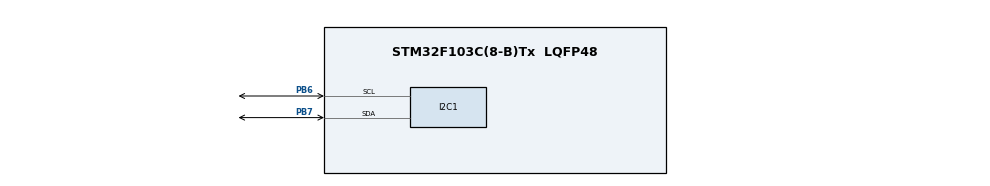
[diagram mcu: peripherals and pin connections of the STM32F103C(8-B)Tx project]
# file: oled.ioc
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Mcu.Family=STM32F1
Mcu.Name=STM32F103C(8-B)Tx
Mcu.Package=LQFP48
NVIC.PriorityGroup=NVIC_PRIORITYGROUP_4
PA13.Mode=Serial_Wire
PA13.Signal=SYS_JTMS-SWDIO
PA14.Mode=Serial_Wire
PA14.Signal=SYS_JTCK-SWCLK
PB6.Mode=I2C
PB6.Signal=I2C1_SCL
PB7.Mode=I2C
PB7.Signal=I2C1_SDA
ProjectManager.HeapSize=0x200
ProjectManager.StackSize=0x400
ProjectManager.TargetToolchain=STM32CubeIDE
RCC.APB1Freq_Value=8000000
RCC.APB2Freq_Value=8000000
board=custom

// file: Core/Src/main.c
/* USER CODE BEGIN Header */
/**
  ******************************************************************************
  * @file           : main.c
  * @brief          : Main program body
  ******************************************************************************
  * @attention
  *
  * <h2><center>&copy; Copyright (c) 2022 STMicroelectronics.
  * All rights reserved.</center></h2>
  *
  * This software component is licensed by ST under BSD 3-Clause license,
  * the "License"; You may not use this file except in compliance with the
  * License. You may obtain a copy of the License at:
  *                        opensource.org/licenses/BSD-3-Clause
  *
  ******************************************************************************
  */
/* USER CODE END Header */
#include "main.h"

/* USER CODE BEGIN Includes */
#include "oled_driver.h"

/* USER CODE END Includes */

I2C_HandleTypeDef hi2c1;

/* USER CODE BEGIN PV */
const uint8_t img[1024] = {
0X00,0X00,0X00,0X00,0X00,0X00,0X00,0X00,0X00,0X00,0X00,0X00,0X00,0X00,0X00,0X00,
0X00,0X00,0X00,0X00,0X00,0X00,0X00,0X00,0X00,0X00,0X00,0X00,0X00,0X00,0X00,0X00,
0X00,0X00,0X00,0X00,0X00,0X00,0X00,0X00,0X00,0X00,0X00,0X00,0X00,0X00,0X00,0X00,
0X00,0X00,0X00,0X00,0X00,0X00,0X00,0X00,0X00,0X00,0X00,0X00,0X00,0X00,0X00,0X00,
0X00,0X00,0X00,0X00,0X00,0X00,0X00,0X00,0X00,0X00,0X00,0X00,0X00,0X00,0X00,0X00,
0X00,0X00,0X00,0X00,0X00,0X00,0X00,0X00,0X00,0X00,0X00,0X00,0X00,0X00,0X00,0X00,
0X00,0X00,0X00,0X00,0X00,0X00,0X00,0X00,0X00,0X00,0X00,0X00,0X00,0X00,0X00,0X00,
0X00,0X00,0X00,0X00,0X00,0X00,0X00,0X00,0X00,0X00,0X00,0X00,0X00,0X00,0X00,0X00,
0X00,0X00,0X00,0X06,0X0F,0X0F,0X0F,0X06,0X00,0X00,0X00,0X00,0X00,0X00,0X00,0X00,
0X00,0X00,0X00,0X80,0X80,0X80,0X00,0X00,0X00,0X00,0X00,0X00,0X00,0X00,0X00,0X00,
0X00,0X00,0X00,0X00,0X00,0X00,0X80,0X80,0X80,0X80,0X00,0X00,0X00,0X00,0X00,0X00,
0X00,0X00,0X00,0X00,0X00,0X80,0X80,0X80,0X80,0X00,0X00,0X00,0X00,0X00,0X00,0X00,
0X00,0X00,0X00,0X00,0X00,0X00,0X00,0X00,0X00,0X00,0X80,0X80,0X00,0X00,0X00,0X00,
0X00,0X00,0X00,0X00,0X00,0X00,0X80,0X80,0X80,0X80,0X00,0X00,0X00,0X00,0X00,0X00,
0X00,0X00,0X00,0X00,0X80,0X80,0X80,0X80,0X00,0X00,0X00,0X00,0X00,0X00,0X00,0X00,
0X00,0X00,0X00,0X00,0X00,0X00,0X80,0X80,0X80,0X80,0X00,0X00,0X00,0X00,0X00,0X00,
0X00,0X00,0X00,0X00,0XFF,0XFF,0XFF,0X00,0X00,0X00,0X00,0X00,0XF0,0XFC,0XFE,0X3E,
0X0F,0X07,0X07,0X03,0X03,0X03,0X07,0X07,0X0F,0XFE,0XFC,0XF8,0XE0,0X00,0X00,0X00,
0X00,0X7C,0XFE,0XFF,0XEF,0XC7,0XC3,0X83,0X83,0X03,0X07,0X07,0X00,0X00,0X00,0X00,
0X00,0X0E,0X87,0X87,0X83,0X83,0XC3,0XC3,0XC3,0XC7,0XFF,0XFE,0XFC,0XE0,0X00,0X00,
0X00,0X00,0X00,0XFF,0XFF,0XFF,0X3C,0X0E,0X07,0X07,0X07,0X07,0X00,0X00,0X00,0XF0,
0XF8,0XFE,0X3E,0X0F,0X07,0X07,0X03,0X03,0X03,0X03,0X07,0X07,0X00,0X00,0X00,0X00,
0X0E,0X87,0X87,0X83,0X83,0XC3,0XC3,0XC3,0XC7,0XFF,0XFE,0XFC,0XE0,0X00,0X00,0X00,
0X00,0X7C,0XFE,0XFF,0XEF,0XC7,0XC3,0X83,0X83,0X03,0X07,0X07,0X00,0X00,0X00,0X00,
0X00,0X00,0X00,0X00,0XFF,0XFF,0XFF,0X00,0X00,0X00,0X00,0X00,0X1F,0X3F,0XFF,0XF8,
0XE0,0XC0,0XC0,0XC0,0XC0,0XC0,0XC0,0XC0,0XF0,0XFF,0X7F,0X3F,0X0F,0X00,0X00,0X00,
0X00,0XC0,0XC0,0XC1,0X81,0X83,0X83,0X83,0XC7,0XFF,0XFF,0X7E,0X3C,0X00,0X00,0X38,
0XFE,0XFF,0XFF,0XC3,0XC1,0X81,0X81,0XC1,0XC1,0X61,0XFF,0XFF,0XFF,0XFF,0X00,0X00,
0X00,0X00,0X00,0XFF,0XFF,0XFF,0X00,0X00,0X00,0X00,0X00,0X00,0X00,0X00,0X00,0X1F,
0X7F,0XFF,0XF8,0XE0,0XC0,0XC0,0XC0,0XC0,0XC0,0XC0,0XC0,0XC0,0X00,0X00,0X38,0XFE,
0XFF,0XFF,0XC3,0XC1,0X81,0X81,0XC1,0XC1,0X61,0XFF,0XFF,0XFF,0XFF,0X00,0X00,0X00,
0X00,0XC0,0XC0,0XC1,0X81,0X83,0X83,0X83,0XC7,0XFF,0XFF,0X7E,0X3C,0X00,0X00,0X00,
0X00,0XC0,0XE0,0XF8,0XFF,0X7F,0X1F,0X00,0X00,0X00,0X00,0X00,0X00,0X00,0X00,0X00,
0X01,0X01,0X01,0X01,0X01,0X01,0X01,0X01,0X00,0X00,0X00,0X00,0X00,0X00,0X00,0X00,
0X00,0X01,0X01,0X01,0X01,0X01,0X01,0X01,0X01,0X01,0X00,0X00,0X00,0X00,0X00,0X00,
0X00,0X01,0X81,0X01,0X11,0X31,0X21,0X61,0X40,0X08,0X19,0X21,0X41,0X01,0X80,0X81,
0X8F,0XB8,0X80,0X01,0X19,0X01,0X00,0X00,0X00,0X00,0X18,0X0F,0X01,0X00,0X80,0XC0,
0X60,0X20,0X00,0X01,0X01,0X01,0X81,0XC1,0XC1,0XE1,0XE1,0XC0,0XC0,0X80,0X80,0X00,
0X01,0X01,0X01,0X01,0X01,0X01,0X01,0X00,0X00,0X01,0X01,0X01,0X01,0X00,0X00,0X00,
0X00,0X01,0X01,0X01,0X01,0X01,0X01,0X01,0X01,0X01,0X00,0X00,0X00,0X00,0X00,0X00,
0X00,0X01,0X01,0X00,0X00,0X00,0X00,0X00,0X00,0X00,0X00,0X00,0X00,0X00,0X00,0X00,
0X00,0X00,0X00,0X00,0X00,0X00,0X00,0X00,0X00,0X00,0X00,0X00,0X00,0X00,0X00,0X00,
0X00,0X00,0X00,0X00,0X00,0X00,0X00,0X80,0X80,0XC0,0XC0,0XE0,0XF0,0XF0,0XF8,0X7C,
0X7E,0X3F,0X1F,0X1F,0X7F,0XFC,0XF8,0XF8,0XFC,0XFE,0XBF,0X1F,0X0F,0X0F,0X0F,0X0F,
0X07,0X07,0X0F,0X0F,0X0F,0X0F,0X0F,0X1E,0X9E,0XBC,0XFC,0XF8,0XF8,0XF0,0XF0,0XF0,
0XF8,0X78,0X7C,0X3E,0X1F,0X1F,0X0F,0X07,0X07,0X03,0X03,0X03,0X07,0X0F,0X0F,0X3F,
0X7E,0X7C,0XF8,0XF0,0XE0,0XE0,0XC0,0XC0,0X80,0X80,0X00,0X00,0X00,0X00,0X00,0X00,
0X00,0X00,0X00,0X00,0X00,0X00,0X00,0X00,0X00,0X00,0X00,0X00,0X00,0X00,0X00,0X00,
0X00,0X00,0X00,0X00,0X80,0X80,0X80,0X80,0X80,0XC0,0XC0,0XC0,0XC0,0XC0,0XE0,0XE0,
0XE0,0XE0,0XE0,0XE0,0XF0,0XF0,0XF0,0XF0,0XF0,0XF8,0XF8,0X78,0X78,0X78,0X78,0X7C,
0X7C,0X3C,0X3C,0X3E,0X1E,0X1F,0X1F,0X0F,0X0F,0X07,0X07,0X03,0X01,0X01,0X00,0X00,
0X00,0X00,0X00,0X00,0X00,0X00,0X01,0X03,0X03,0X07,0X0F,0X1F,0X3E,0X7E,0X7C,0XF8,
0XF0,0XF8,0XFC,0XFC,0XFE,0XDF,0XCF,0X8F,0X8F,0X07,0X07,0X07,0X03,0X03,0X01,0X00,
0X00,0X00,0X00,0X00,0X00,0X00,0X00,0X00,0X00,0X00,0X00,0X00,0X00,0X00,0X00,0X00,
0X00,0X00,0X00,0X01,0X01,0X03,0X03,0X07,0X07,0X0F,0X0F,0X1F,0X1E,0X1E,0X3C,0X3C,
0X3C,0X3C,0X3C,0X3C,0X78,0X78,0X78,0XF8,0XF0,0XF0,0XF0,0XE0,0XE0,0XC0,0XC0,0XC0,
0X00,0X00,0X02,0X07,0X07,0X07,0X07,0X07,0X07,0X07,0X07,0X03,0X03,0X03,0X03,0X03,
0X01,0X01,0X01,0X01,0X01,0X01,0X00,0X00,0X00,0X00,0X00,0X00,0X00,0X00,0X00,0X00,
0X00,0X00,0X00,0X00,0X00,0X00,0X00,0X00,0X00,0X00,0X00,0X00,0X00,0X00,0X00,0X00,
0X00,0X00,0X00,0X00,0X00,0X00,0X00,0X00,0X00,0X00,0X00,0X00,0X00,0X00,0X00,0X00,
0X00,0X01,0X01,0X01,0X03,0X03,0X07,0X07,0X0F,0X1F,0X1E,0X3E,0X3C,0X3C,0X00,0X00,
0X00,0X00,0X00,0X00,0X00,0X00,0X00,0X00,0X00,0X00,0X00,0X00,0X00,0X00,0X00,0X00,
0X00,0X00,0X00,0X00,0X00,0X00,0X00,0X00,0X00,0X00,0X00,0X00,0X00,0X00,0X00,0X00,
0X00,0X00,0X00,0X00,0X00,0X00,0X00,0X00,0X00,0X00,0X01,0X01,0X03,0X03,0X03,0X07,
};

/* USER CODE END PV */

void SystemClock_Config(void);
static void MX_GPIO_Init(void);
static void MX_I2C1_Init(void);

int main(void)
{

  /* MCU Configuration--------------------------------------------------------*/

  /* Reset of all peripherals, Initializes the Flash interface and the Systick. */
  HAL_Init();

  /* Configure the system clock */
  SystemClock_Config();

  /* Initialize all configured peripherals */
  MX_GPIO_Init();
  MX_I2C1_Init();
  /* USER CODE BEGIN 2 */

  init_oled();

  //for(uint8_t i=0; i<100; i++)
	  //set_pixel_oled(i, 15);

  draw_bitmap_oled(img, 0, 0, 128, 64);

  /* USER CODE END 2 */

  /* Infinite loop */
  while (1)
  {

  }
}

void SystemClock_Config(void)
{
  RCC_OscInitTypeDef RCC_OscInitStruct = {0};
  RCC_ClkInitTypeDef RCC_ClkInitStruct = {0};

  /** Initializes the RCC Oscillators according to the specified parameters
  * in the RCC_OscInitTypeDef structure.
  */
  RCC_OscInitStruct.OscillatorType = RCC_OSCILLATORTYPE_HSI;
  RCC_OscInitStruct.HSIState = RCC_HSI_ON;
  RCC_OscInitStruct.HSICalibrationValue = RCC_HSICALIBRATION_DEFAULT;
  RCC_OscInitStruct.PLL.PLLState = RCC_PLL_NONE;
  if (HAL_RCC_OscConfig(&RCC_OscInitStruct) != HAL_OK)
  {
    Error_Handler();
  }
  /** Initializes the CPU, AHB and APB buses clocks
  */
  RCC_ClkInitStruct.ClockType = RCC_CLOCKTYPE_HCLK|RCC_CLOCKTYPE_SYSCLK
                              |RCC_CLOCKTYPE_PCLK1|RCC_CLOCKTYPE_PCLK2;
  RCC_ClkInitStruct.SYSCLKSource = RCC_SYSCLKSOURCE_HSI;
  RCC_ClkInitStruct.AHBCLKDivider = RCC_SYSCLK_DIV1;
  RCC_ClkInitStruct.APB1CLKDivider = RCC_HCLK_DIV1;
  RCC_ClkInitStruct.APB2CLKDivider = RCC_HCLK_DIV1;

  if (HAL_RCC_ClockConfig(&RCC_ClkInitStruct, FLASH_LATENCY_0) != HAL_OK)
  {
    Error_Handler();
  }
}

static void MX_I2C1_Init(void)
{

  hi2c1.Instance = I2C1;
  hi2c1.Init.ClockSpeed = 100000;
  hi2c1.Init.DutyCycle = I2C_DUTYCYCLE_2;
  hi2c1.Init.OwnAddress1 = 0;
  hi2c1.Init.AddressingMode = I2C_ADDRESSINGMODE_7BIT;
  hi2c1.Init.DualAddressMode = I2C_DUALADDRESS_DISABLE;
  hi2c1.Init.OwnAddress2 = 0;
  hi2c1.Init.GeneralCallMode = I2C_GENERALCALL_DISABLE;
  hi2c1.Init.NoStretchMode = I2C_NOSTRETCH_DISABLE;
  if (HAL_I2C_Init(&hi2c1) != HAL_OK)
  {
    Error_Handler();
  }

}

static void MX_GPIO_Init(void)
{

  /* GPIO Ports Clock Enable */
  __HAL_RCC_GPIOA_CLK_ENABLE();
  __HAL_RCC_GPIOB_CLK_ENABLE();

}

void Error_Handler(void)
{
  __disable_irq();
  while (1)
  {
  }
}

/************************ (C) COPYRIGHT STMicroelectronics *****END OF FILE****/
